VERSION ""

NS_ :

BS_:

BU_: BITSTREAM daq torque_vector InverterA OrionBMS Dashboard Main_Module bootloader InverterB Steering a_box PDU DAQ

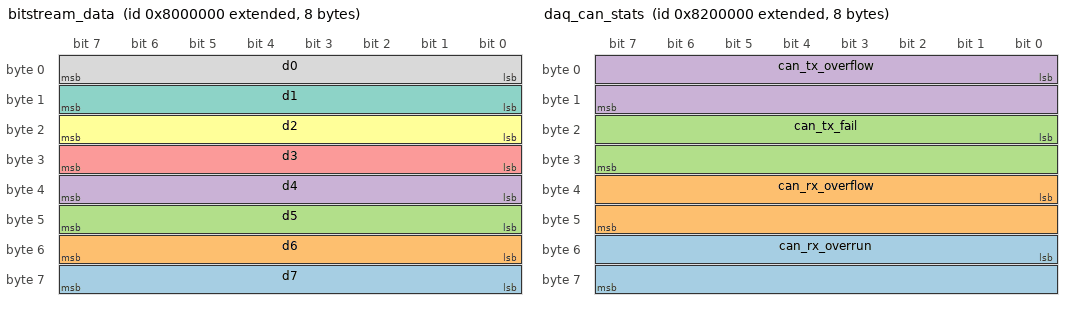
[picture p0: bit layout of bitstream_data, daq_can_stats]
BO_ 2281701376 bitstream_data: 8 BITSTREAM
 SG_ d7 : 56|8@1+ (1,0) [0|0] "" Vector__XXX
 SG_ d6 : 48|8@1+ (1,0) [0|0] "" Vector__XXX
 SG_ d5 : 40|8@1+ (1,0) [0|0] "" Vector__XXX
 SG_ d4 : 32|8@1+ (1,0) [0|0] "" Vector__XXX
 SG_ d3 : 24|8@1+ (1,0) [0|0] "" Vector__XXX
 SG_ d2 : 16|8@1+ (1,0) [0|0] "" Vector__XXX
 SG_ d1 : 8|8@1+ (1,0) [0|0] "" Vector__XXX
 SG_ d0 : 0|8@1+ (1,0) [0|0] "" Vector__XXX

BO_ 2281701888 bitstream_request: 5 BITSTREAM
 SG_ download_size : 1|32@1+ (1,0) [0|0] "" Vector__XXX
 SG_ download_request : 0|1@1+ (1,0) [0|0] "" Vector__XXX

BO_ 2281702400 main_module_bl_cmd: 5 BITSTREAM
 SG_ data : 8|32@1+ (1,0) [0|0] "" Vector__XXX
 SG_ cmd : 0|8@1+ (1,0) [0|0] "" Vector__XXX

BO_ 2281702912 dashboard_bl_cmd: 5 BITSTREAM
 SG_ data : 8|32@1+ (1,0) [0|0] "" Vector__XXX
 SG_ cmd : 0|8@1+ (1,0) [0|0] "" Vector__XXX

BO_ 2281703424 torquevector_bl_cmd: 5 BITSTREAM
 SG_ data : 8|32@1+ (1,0) [0|0] "" Vector__XXX
 SG_ cmd : 0|8@1+ (1,0) [0|0] "" Vector__XXX

BO_ 2281703936 a_box_bl_cmd: 5 BITSTREAM
 SG_ data : 8|32@1+ (1,0) [0|0] "" Vector__XXX
 SG_ cmd : 0|8@1+ (1,0) [0|0] "" Vector__XXX

BO_ 2281704448 pdu_bl_cmd: 5 BITSTREAM
 SG_ data : 8|32@1+ (1,0) [0|0] "" Vector__XXX
 SG_ cmd : 0|8@1+ (1,0) [0|0] "" Vector__XXX

BO_ 2281704960 l4_testing_bl_cmd: 5 BITSTREAM
 SG_ data : 8|32@1+ (1,0) [0|0] "" Vector__XXX
 SG_ cmd : 0|8@1+ (1,0) [0|0] "" Vector__XXX

BO_ 2281705472 f4_testing_bl_cmd: 5 BITSTREAM
 SG_ data : 8|32@1+ (1,0) [0|0] "" Vector__XXX
 SG_ cmd : 0|8@1+ (1,0) [0|0] "" Vector__XXX

BO_ 2281705984 f7_testing_bl_cmd: 5 BITSTREAM
 SG_ data : 8|32@1+ (1,0) [0|0] "" Vector__XXX
 SG_ cmd : 0|8@1+ (1,0) [0|0] "" Vector__XXX

BO_ 2281706496 daq_bl_cmd: 5 BITSTREAM
 SG_ data : 8|32@1+ (1,0) [0|0] "" Vector__XXX
 SG_ cmd : 0|8@1+ (1,0) [0|0] "" Vector__XXX

BO_ 2281707008 set_fault: 3 BITSTREAM
 SG_ value : 16|1@1+ (1,0) [0|0] "" Vector__XXX
 SG_ id : 0|16@1+ (1,0) [0|0] "" Vector__XXX

BO_ 2281707520 return_fault_control: 2 BITSTREAM
 SG_ id : 0|16@1+ (1,0) [0|0] "" Vector__XXX

BO_ 2283798528 daq_can_stats: 8 daq
 SG_ can_rx_overrun : 48|16@1+ (1,0) [0|0] "" Vector__XXX
 SG_ can_rx_overflow : 32|16@1+ (1,0) [0|0] "" Vector__XXX
 SG_ can_tx_fail : 16|16@1+ (1,0) [0|0] "" Vector__XXX
 SG_ can_tx_overflow : 0|16@1+ (1,0) [0|0] "" Vector__XXX

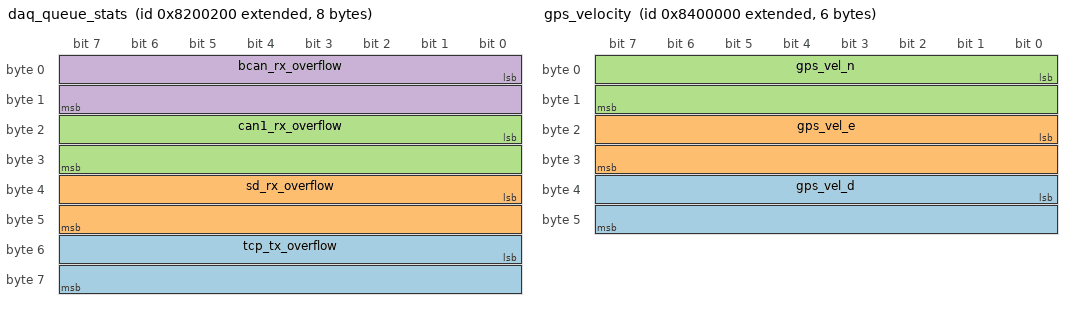
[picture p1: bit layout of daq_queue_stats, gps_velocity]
BO_ 2283799040 daq_queue_stats: 8 daq
 SG_ tcp_tx_overflow : 48|16@1+ (1,0) [0|0] "" Vector__XXX
 SG_ sd_rx_overflow : 32|16@1+ (1,0) [0|0] "" Vector__XXX
 SG_ can1_rx_overflow : 16|16@1+ (1,0) [0|0] "" Vector__XXX
 SG_ bcan_rx_overflow : 0|16@1+ (1,0) [0|0] "" Vector__XXX

BO_ 2418017280 daq_version: 8 daq
 SG_ git_hash : 0|64@1+ (1,0) [0|0] "" Vector__XXX

BO_ 2285895680 gps_velocity: 6 torque_vector
 SG_ gps_vel_d : 32|16@1- (1,0) [0|0] "m/s" Vector__XXX
 SG_ gps_vel_e : 16|16@1- (1,0) [0|0] "m/s" Vector__XXX
 SG_ gps_vel_n : 0|16@1- (1,0) [0|0] "m/s" Vector__XXX

BO_ 2285896192 gps_speed: 4 torque_vector
 SG_ gps_heading : 16|16@1- (1,0) [0|0] "none" Vector__XXX
 SG_ gps_speed : 0|16@1- (1,0) [0|0] "m/s" Vector__XXX

BO_ 2285896704 gps_position: 2 torque_vector
 SG_ height : 0|16@1- (1,0) [0|0] "m" Vector__XXX

BO_ 2285897216 gps_coordinates: 8 torque_vector
 SG_ longitude : 32|32@1- (1,0) [0|0] "deg" Vector__XXX
 SG_ latitude : 0|32@1- (1,0) [0|0] "deg" Vector__XXX

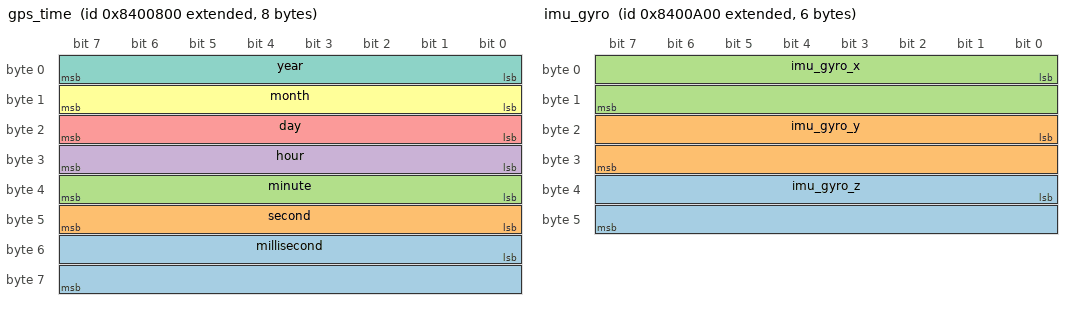
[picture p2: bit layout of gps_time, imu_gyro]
BO_ 2285897728 gps_time: 8 torque_vector
 SG_ millisecond : 48|16@1+ (1,0) [0|0] "ms" Vector__XXX
 SG_ second : 40|8@1+ (1,0) [0|0] "s" Vector__XXX
 SG_ minute : 32|8@1+ (1,0) [0|0] "m" Vector__XXX
 SG_ hour : 24|8@1+ (1,0) [0|0] "h" Vector__XXX
 SG_ day : 16|8@1+ (1,0) [0|0] "d" Vector__XXX
 SG_ month : 8|8@1+ (1,0) [0|0] "mo" Vector__XXX
 SG_ year : 0|8@1+ (1,0) [0|0] "yr" Vector__XXX

BO_ 2285898240 imu_gyro: 6 torque_vector
 SG_ imu_gyro_z : 32|16@1- (1,0) [0|0] "rad/s" Vector__XXX
 SG_ imu_gyro_y : 16|16@1- (1,0) [0|0] "rad/s" Vector__XXX
 SG_ imu_gyro_x : 0|16@1- (1,0) [0|0] "rad/s" Vector__XXX

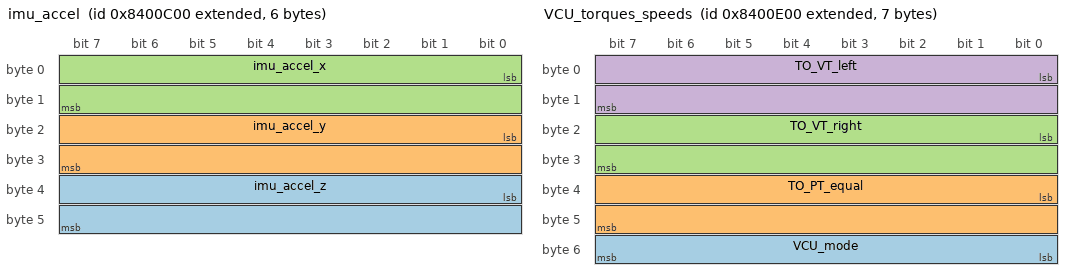
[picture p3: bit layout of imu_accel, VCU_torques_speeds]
BO_ 2285898752 imu_accel: 6 torque_vector
 SG_ imu_accel_z : 32|16@1- (1,0) [0|0] "m/s^2" Vector__XXX
 SG_ imu_accel_y : 16|16@1- (1,0) [0|0] "m/s^2" Vector__XXX
 SG_ imu_accel_x : 0|16@1- (1,0) [0|0] "m/s^2" Vector__XXX

BO_ 2285899264 VCU_torques_speeds: 7 torque_vector
 SG_ VCU_mode : 48|8@1- (1,0) [0|0] "" Vector__XXX
 SG_ TO_PT_equal : 32|16@1- (1,0) [0|0] "Nm" Vector__XXX
 SG_ TO_VT_right : 16|16@1- (1,0) [0|0] "Nm" Vector__XXX
 SG_ TO_VT_left : 0|16@1- (1,0) [0|0] "Nm" Vector__XXX

BO_ 2285899776 vcu_soc_estimate: 4 torque_vector
 SG_ Voc_estimate : 16|16@1- (1,0) [0|0] "V" Vector__XXX
 SG_ SOC_estimate : 0|16@1- (1,0) [0|0] "none" Vector__XXX

BO_ 2285900288 drive_modes: 3 torque_vector
 SG_ WS_VS_equal : 8|16@1- (1,0) [0|0] "rad/s" Vector__XXX
 SG_ VT_mode : 0|8@1- (1,0) [0|0] "" Vector__XXX

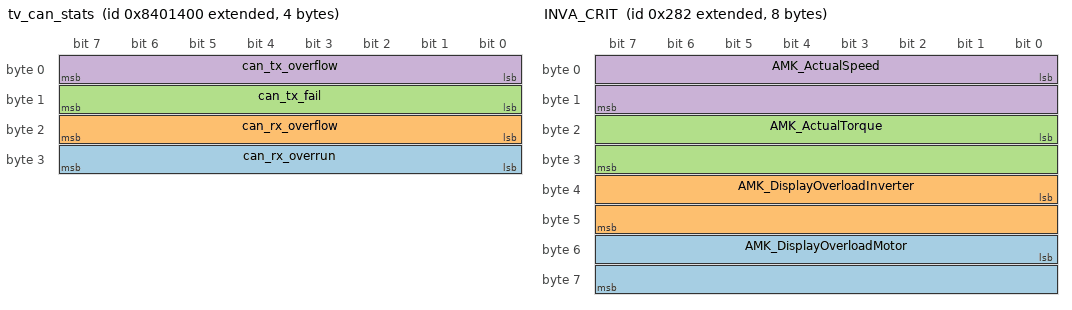
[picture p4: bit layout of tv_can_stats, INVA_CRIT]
BO_ 2285900800 tv_can_stats: 4 torque_vector
 SG_ can_rx_overrun : 24|8@1+ (1,0) [0|0] "" Vector__XXX
 SG_ can_rx_overflow : 16|8@1+ (1,0) [0|0] "" Vector__XXX
 SG_ can_tx_fail : 8|8@1+ (1,0) [0|0] "" Vector__XXX
 SG_ can_tx_overflow : 0|8@1+ (1,0) [0|0] "" Vector__XXX

BO_ 2420119040 tv_version: 8 torque_vector
 SG_ git_hash : 0|64@1+ (1,0) [0|0] "" Vector__XXX

BO_ 2151684096 fault_sync_torque_vector: 3 torque_vector
 SG_ latched : 16|1@1+ (1,0) [0|0] "" Vector__XXX
 SG_ idx : 0|16@1+ (1,0) [0|0] "" Vector__XXX

BO_ 2147484290 INVA_CRIT: 8 InverterA
 SG_ AMK_DisplayOverloadMotor : 48|16@1+ (1,0) [0|0] "" Vector__XXX
 SG_ AMK_DisplayOverloadInverter : 32|16@1+ (1,0) [0|0] "" Vector__XXX
 SG_ AMK_ActualTorque : 16|16@1- (1,0) [0|0] "%" Vector__XXX
 SG_ AMK_ActualSpeed : 0|16@1- (1,0) [0|0] "rpm" Vector__XXX

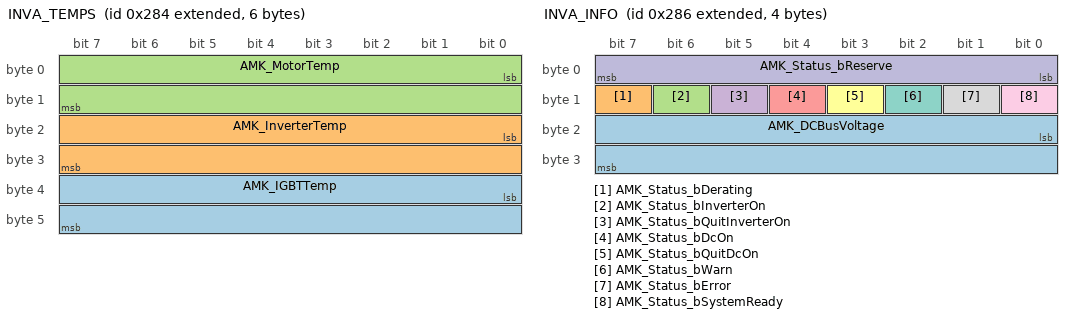
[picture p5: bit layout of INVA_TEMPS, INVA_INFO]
BO_ 2147484292 INVA_TEMPS: 6 InverterA
 SG_ AMK_IGBTTemp : 32|16@1- (1,0) [0|0] "C" Vector__XXX
 SG_ AMK_InverterTemp : 16|16@1- (1,0) [0|0] "C" Vector__XXX
 SG_ AMK_MotorTemp : 0|16@1- (1,0) [0|0] "C" Vector__XXX

BO_ 2147484294 INVA_INFO: 4 InverterA
 SG_ AMK_DCBusVoltage : 16|16@1+ (1,0) [0|0] "V" Vector__XXX
 SG_ AMK_Status_bDerating : 15|1@1+ (1,0) [0|0] "" Vector__XXX
 SG_ AMK_Status_bInverterOn : 14|1@1+ (1,0) [0|0] "" Vector__XXX
 SG_ AMK_Status_bQuitInverterOn : 13|1@1+ (1,0) [0|0] "" Vector__XXX
 SG_ AMK_Status_bDcOn : 12|1@1+ (1,0) [0|0] "" Vector__XXX
 SG_ AMK_Status_bQuitDcOn : 11|1@1+ (1,0) [0|0] "" Vector__XXX
 SG_ AMK_Status_bWarn : 10|1@1+ (1,0) [0|0] "" Vector__XXX
 SG_ AMK_Status_bError : 9|1@1+ (1,0) [0|0] "" Vector__XXX
 SG_ AMK_Status_bSystemReady : 8|1@1+ (1,0) [0|0] "" Vector__XXX
 SG_ AMK_Status_bReserve : 0|8@1+ (1,0) [0|0] "" Vector__XXX

BO_ 2147484296 INVA_ERR_1: 8 InverterA
 SG_ AMK_ErrorInfo1 : 32|32@1+ (1,0) [0|0] "" Vector__XXX
 SG_ AMK_DiagnosticNumber : 0|32@1+ (1,0) [0|0] "" Vector__XXX

BO_ 2147484304 INVA_ERR_2: 8 InverterA
 SG_ AMK_ErrorInfo3 : 32|32@1+ (1,0) [0|0] "" Vector__XXX
 SG_ AMK_ErrorInfo2 : 0|32@1+ (1,0) [0|0] "" Vector__XXX

BO_ 2147484306 INVA_PHASE_I: 4 InverterA
 SG_ AMK_PhaseUCurrent : 0|32@1- (1,0) [0|0] "" Vector__XXX

BO_ 2290089984 orion_info: 7 OrionBMS
 SG_ pack_soc : 48|8@1+ (1,0) [0|0] "%" Vector__XXX
 SG_ pack_ccl : 32|16@1+ (1,0) [0|0] "A" Vector__XXX
 SG_ pack_dcl : 16|16@1+ (1,0) [0|0] "A" Vector__XXX
 SG_ multi_output_1 : 15|1@1+ (1,0) [0|0] "" Vector__XXX
 SG_ multi_enable : 14|1@1+ (1,0) [0|0] "" Vector__XXX
 SG_ multi_output_4 : 13|1@1+ (1,0) [0|0] "" Vector__XXX
 SG_ multi_output_3 : 12|1@1+ (1,0) [0|0] "" Vector__XXX
 SG_ multi_output_2 : 11|1@1+ (1,0) [0|0] "" Vector__XXX
 SG_ reserved : 10|1@1+ (1,0) [0|0] "" Vector__XXX
 SG_ multi_input_3 : 9|1@1+ (1,0) [0|0] "" Vector__XXX
 SG_ multi_input_2 : 8|1@1+ (1,0) [0|0] "" Vector__XXX
 SG_ is_charging : 7|1@1+ (1,0) [0|0] "" Vector__XXX
 SG_ is_ready : 6|1@1+ (1,0) [0|0] "" Vector__XXX
 SG_ always_on : 5|1@1+ (1,0) [0|0] "" Vector__XXX
 SG_ multi_input : 4|1@1+ (1,0) [0|0] "" Vector__XXX
 SG_ dtc_status : 3|1@1+ (1,0) [0|0] "" Vector__XXX
 SG_ charger_safety : 2|1@1+ (1,0) [0|0] "" Vector__XXX
 SG_ charge_enable : 1|1@1+ (1,0) [0|0] "" Vector__XXX
 SG_ discharge_enable : 0|1@1+ (1,0) [0|0] "" Vector__XXX

BO_ 2290090496 orion_currents_volts: 4 OrionBMS
 SG_ pack_voltage : 16|16@1+ (1,0) [0|0] "V" Vector__XXX
 SG_ pack_current : 0|16@1- (1,0) [0|0] "A" Vector__XXX

BO_ 2290091008 orion_errors: 4 OrionBMS
 SG_ charge_limit_enforce : 31|1@1+ (1,0) [0|0] "" Vector__XXX
 SG_ input_psu : 30|1@1+ (1,0) [0|0] "" Vector__XXX
 SG_ hv_isolation : 29|1@1+ (1,0) [0|0] "" Vector__XXX
 SG_ redundant_psu : 28|1@1+ (1,0) [0|0] "" Vector__XXX
 SG_ external_comms : 27|1@1+ (1,0) [0|0] "" Vector__XXX
 SG_ thermistor : 26|1@1+ (1,0) [0|0] "" Vector__XXX
 SG_ fan_monitor : 25|1@1+ (1,0) [0|0] "" Vector__XXX
 SG_ weak_pack : 24|1@1+ (1,0) [0|0] "" Vector__XXX
 SG_ cell_asic : 23|1@1+ (1,0) [0|0] "" Vector__XXX
 SG_ max_cellv_o5v : 22|1@1+ (1,0) [0|0] "" Vector__XXX
 SG_ current_sensor : 21|1@1+ (1,0) [0|0] "" Vector__XXX
 SG_ open_wire : 20|1@1+ (1,0) [0|0] "" Vector__XXX
 SG_ low_cellv : 19|1@1+ (1,0) [0|0] "" Vector__XXX
 SG_ weak_cell : 18|1@1+ (1,0) [0|0] "" Vector__XXX
 SG_ cell_balancing_foff : 17|1@1+ (1,0) [0|0] "" Vector__XXX
 SG_ internal_comms : 16|1@1+ (1,0) [0|0] "" Vector__XXX
 SG_ reserved7 : 15|1@1+ (1,0) [0|0] "" Vector__XXX
 SG_ reserved6 : 14|1@1+ (1,0) [0|0] "" Vector__XXX
 SG_ reserved5 : 13|1@1+ (1,0) [0|0] "" Vector__XXX
 SG_ reserved4 : 12|1@1+ (1,0) [0|0] "" Vector__XXX
 SG_ reserved3 : 11|1@1+ (1,0) [0|0] "" Vector__XXX
 SG_ reserved2 : 10|1@1+ (1,0) [0|0] "" Vector__XXX
 SG_ reserved1 : 9|1@1+ (1,0) [0|0] "" Vector__XXX
 SG_ reserved0 : 8|1@1+ (1,0) [0|0] "" Vector__XXX
 SG_ pack_overheat : 7|1@1+ (1,0) [0|0] "" Vector__XXX
 SG_ min_cellv_low : 6|1@1+ (1,0) [0|0] "" Vector__XXX
 SG_ max_cellv_high : 5|1@1+ (1,0) [0|0] "" Vector__XXX
 SG_ software : 4|1@1+ (1,0) [0|0] "" Vector__XXX
 SG_ heatsink_thermistor : 3|1@1+ (1,0) [0|0] "" Vector__XXX
 SG_ internal_hardware : 2|1@1+ (1,0) [0|0] "" Vector__XXX
 SG_ charger_safety_relay : 1|1@1+ (1,0) [0|0] "" Vector__XXX
 SG_ discharge_limit_enforce : 0|1@1+ (1,0) [0|0] "" Vector__XXX

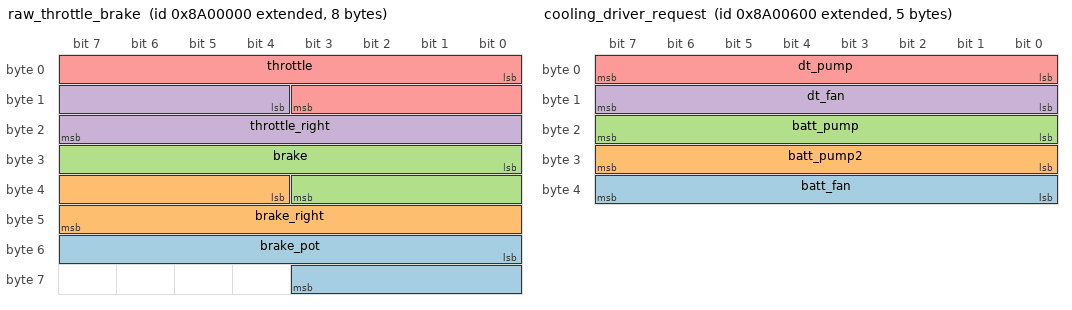
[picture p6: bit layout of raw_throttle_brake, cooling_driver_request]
BO_ 2292187136 raw_throttle_brake: 8 Dashboard
 SG_ brake_pot : 48|12@1+ (1,0) [0|0] "%" Vector__XXX
 SG_ brake_right : 36|12@1+ (1,0) [0|0] "%" Vector__XXX
 SG_ brake : 24|12@1+ (1,0) [0|0] "%" Vector__XXX
 SG_ throttle_right : 12|12@1+ (1,0) [0|0] "%" Vector__XXX
 SG_ throttle : 0|12@1+ (1,0) [0|0] "%" Vector__XXX

BO_ 2292187648 shock_front: 4 Dashboard
 SG_ right_shock : 16|16@1- (1,0) [0|0] "mm" Vector__XXX
 SG_ left_shock : 0|16@1- (1,0) [0|0] "mm" Vector__XXX

BO_ 2292188160 load_sensor_readings_dash: 8 Dashboard
 SG_ right_load_sensor : 32|32@1- (1,0) [0|0] "N" Vector__XXX
 SG_ left_load_sensor : 0|32@1- (1,0) [0|0] "N" Vector__XXX

BO_ 2292188672 cooling_driver_request: 5 Dashboard
 SG_ batt_fan : 32|8@1+ (1,0) [0|100] "%" Vector__XXX
 SG_ batt_pump2 : 24|8@1+ (1,0) [0|0] "" Vector__XXX
 SG_ batt_pump : 16|8@1+ (1,0) [0|0] "" Vector__XXX
 SG_ dt_fan : 8|8@1+ (1,0) [0|100] "%" Vector__XXX
 SG_ dt_pump : 0|8@1+ (1,0) [0|0] "" Vector__XXX

BO_ 2292189184 filt_throttle_brake: 3 Dashboard
 SG_ brake : 12|12@1+ (1,0) [0|0] "%" Vector__XXX
 SG_ throttle : 0|12@1+ (1,0) [0|0] "%" Vector__XXX

BO_ 2292189696 start_button: 1 Dashboard
 SG_ start : 0|1@1+ (1,0) [0|0] "" Vector__XXX

BO_ 2292190208 dashboard_mcu_temp: 2 Dashboard
 SG_ mcu_temp : 0|16@1- (1,0) [0|0] "" Vector__XXX

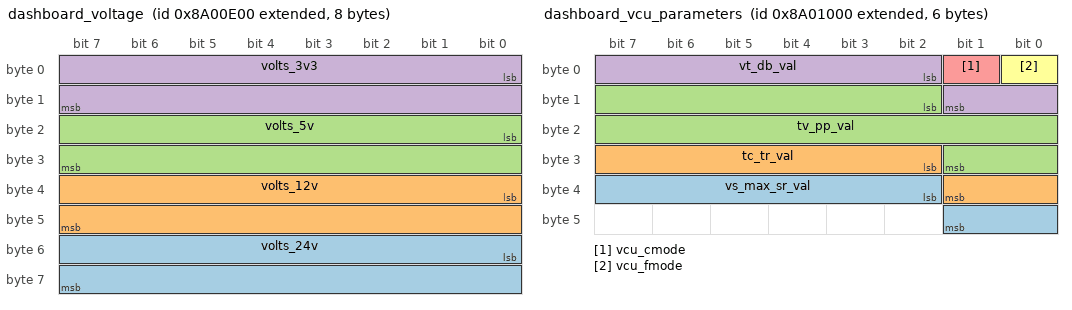
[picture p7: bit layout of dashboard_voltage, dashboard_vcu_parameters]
BO_ 2292190720 dashboard_voltage: 8 Dashboard
 SG_ volts_24v : 48|16@1+ (1,0) [0|0] "V" Vector__XXX
 SG_ volts_12v : 32|16@1+ (1,0) [0|0] "V" Vector__XXX
 SG_ volts_5v : 16|16@1+ (1,0) [0|0] "V" Vector__XXX
 SG_ volts_3v3 : 0|16@1+ (1,0) [0|0] "V" Vector__XXX

BO_ 2292191232 dashboard_vcu_parameters: 6 Dashboard
 SG_ vs_max_sr_val : 34|8@1+ (1,0) [0|0] "" Vector__XXX
 SG_ tc_tr_val : 26|8@1+ (1,0) [0|0] "" Vector__XXX
 SG_ tv_pp_val : 10|16@1+ (1,0) [0|0] "" Vector__XXX
 SG_ vt_db_val : 2|8@1+ (1,0) [0|0] "" Vector__XXX
 SG_ vcu_cmode : 1|1@1+ (1,0) [0|0] "" Vector__XXX
 SG_ vcu_fmode : 0|1@1+ (1,0) [0|0] "" Vector__XXX

BO_ 2292191744 dashboard_start_logging: 1 Dashboard
 SG_ logging_enabled : 0|1@1+ (1,0) [0|0] "" Vector__XXX

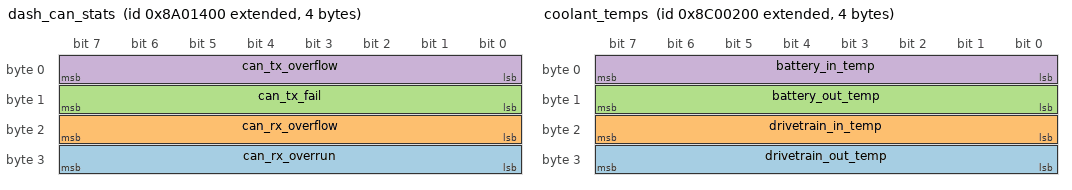
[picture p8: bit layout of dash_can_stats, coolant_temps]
BO_ 2292192256 dash_can_stats: 4 Dashboard
 SG_ can_rx_overrun : 24|8@1+ (1,0) [0|0] "" Vector__XXX
 SG_ can_rx_overflow : 16|8@1+ (1,0) [0|0] "" Vector__XXX
 SG_ can_tx_fail : 8|8@1+ (1,0) [0|0] "" Vector__XXX
 SG_ can_tx_overflow : 0|8@1+ (1,0) [0|0] "" Vector__XXX

BO_ 2426410496 dash_version: 8 Dashboard
 SG_ git_hash : 0|64@1+ (1,0) [0|0] "" Vector__XXX

BO_ 2157975552 fault_sync_dashboard: 3 Dashboard
 SG_ latched : 16|1@1+ (1,0) [0|0] "" Vector__XXX
 SG_ idx : 0|16@1+ (1,0) [0|0] "" Vector__XXX

BO_ 2292193792 daq_response_DASHBOARD_VCAN: 8 Dashboard
 SG_ daq_response : 0|64@1+ (1,0) [0|0] "" Vector__XXX

BO_ 2294284288 main_hb: 2 Main_Module
 SG_ precharge_state : 8|1@1+ (1,0) [0|0] "" Vector__XXX
 SG_ car_state : 0|8@1+ (1,0) [0|0] "" Vector__XXX

BO_ 2294284800 coolant_temps: 4 Main_Module
 SG_ drivetrain_out_temp : 24|8@1- (1,0) [0|0] "C" Vector__XXX
 SG_ drivetrain_in_temp : 16|8@1- (1,0) [0|0] "C" Vector__XXX
 SG_ battery_out_temp : 8|8@1- (1,0) [0|0] "C" Vector__XXX
 SG_ battery_in_temp : 0|8@1- (1,0) [0|0] "C" Vector__XXX

BO_ 2294285312 gearbox: 2 Main_Module
 SG_ r_temp : 8|8@1- (1,0) [0|0] "C" Vector__XXX
 SG_ l_temp : 0|8@1- (1,0) [0|0] "C" Vector__XXX

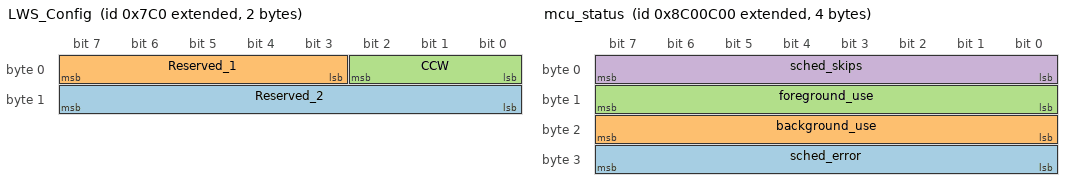
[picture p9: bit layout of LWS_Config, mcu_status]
BO_ 2147485632 LWS_Config: 2 Main_Module
 SG_ Reserved_2 : 8|8@1+ (1,0) [0|0] "" Vector__XXX
 SG_ Reserved_1 : 3|5@1+ (1,0) [0|0] "" Vector__XXX
 SG_ CCW : 0|3@1+ (1,0) [0|0] "" Vector__XXX

BO_ 2294286336 load_sensor_readings: 8 Main_Module
 SG_ right_load_sensor : 32|32@1- (1,0) [0|0] "N" Vector__XXX
 SG_ left_load_sensor : 0|32@1- (1,0) [0|0] "N" Vector__XXX

BO_ 2294286848 shock_rear: 4 Main_Module
 SG_ right_shock : 16|16@1- (1,0) [0|0] "mm" Vector__XXX
 SG_ left_shock : 0|16@1- (1,0) [0|0] "mm" Vector__XXX

BO_ 2294287360 mcu_status: 4 Main_Module
 SG_ sched_error : 24|8@1+ (1,0) [0|0] "" Vector__XXX
 SG_ background_use : 16|8@1+ (1,0) [0|0] "" Vector__XXX
 SG_ foreground_use : 8|8@1+ (1,0) [0|0] "" Vector__XXX
 SG_ sched_skips : 0|8@1+ (1,0) [0|0] "" Vector__XXX

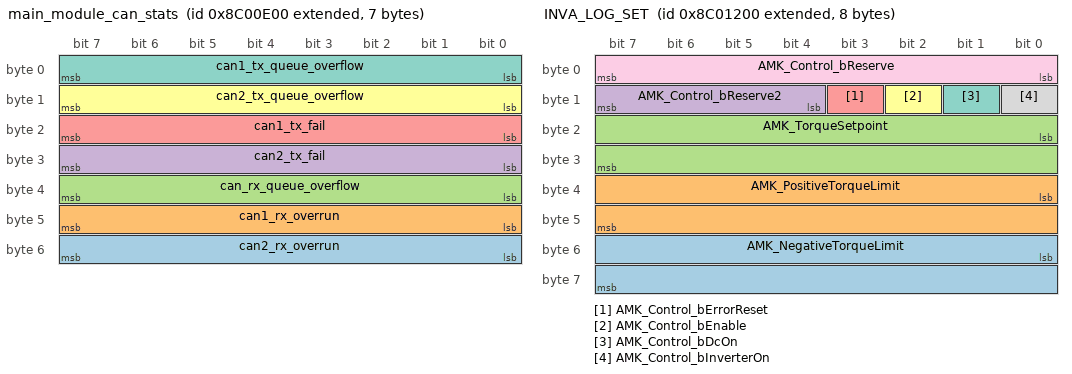
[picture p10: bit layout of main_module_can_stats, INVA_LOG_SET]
BO_ 2294287872 main_module_can_stats: 7 Main_Module
 SG_ can2_rx_overrun : 48|8@1+ (1,0) [0|0] "" Vector__XXX
 SG_ can1_rx_overrun : 40|8@1+ (1,0) [0|0] "" Vector__XXX
 SG_ can_rx_queue_overflow : 32|8@1+ (1,0) [0|0] "" Vector__XXX
 SG_ can2_tx_fail : 24|8@1+ (1,0) [0|0] "" Vector__XXX
 SG_ can1_tx_fail : 16|8@1+ (1,0) [0|0] "" Vector__XXX
 SG_ can2_tx_queue_overflow : 8|8@1+ (1,0) [0|0] "" Vector__XXX
 SG_ can1_tx_queue_overflow : 0|8@1+ (1,0) [0|0] "" Vector__XXX

BO_ 2294288384 num_mc_skips: 4 Main_Module
 SG_ noise_l : 16|16@1+ (1,0) [0|0] "" Vector__XXX
 SG_ noise_r : 0|16@1+ (1,0) [0|0] "" Vector__XXX

BO_ 2294288896 INVA_LOG_SET: 8 Main_Module
 SG_ AMK_NegativeTorqueLimit : 48|16@1- (1,0) [0|0] "Nm" Vector__XXX
 SG_ AMK_PositiveTorqueLimit : 32|16@1- (1,0) [0|0] "Nm" Vector__XXX
 SG_ AMK_TorqueSetpoint : 16|16@1- (1,0) [0|0] "Nm" Vector__XXX
 SG_ AMK_Control_bReserve2 : 12|4@1+ (1,0) [0|0] "" Vector__XXX
 SG_ AMK_Control_bErrorReset : 11|1@1+ (1,0) [0|0] "" Vector__XXX
 SG_ AMK_Control_bEnable : 10|1@1+ (1,0) [0|0] "" Vector__XXX
 SG_ AMK_Control_bDcOn : 9|1@1+ (1,0) [0|0] "" Vector__XXX
 SG_ AMK_Control_bInverterOn : 8|1@1+ (1,0) [0|0] "" Vector__XXX
 SG_ AMK_Control_bReserve : 0|8@1+ (1,0) [0|0] "" Vector__XXX

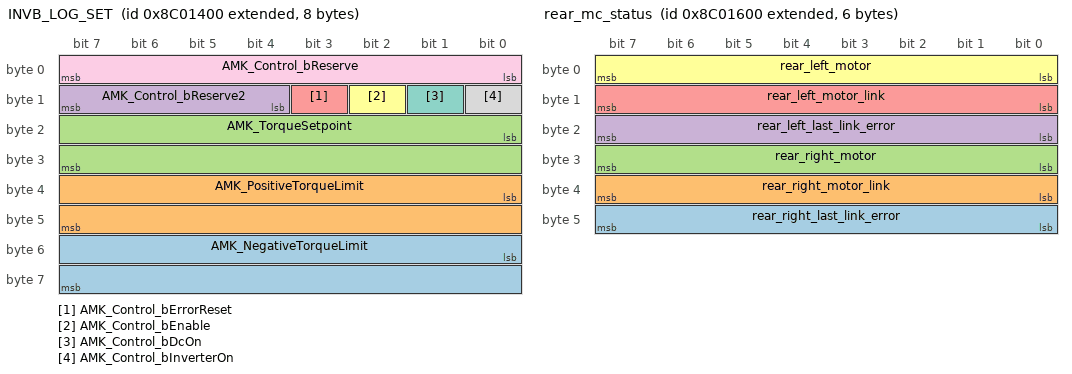
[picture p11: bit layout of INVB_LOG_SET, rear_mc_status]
BO_ 2294289408 INVB_LOG_SET: 8 Main_Module
 SG_ AMK_NegativeTorqueLimit : 48|16@1- (1,0) [0|0] "Nm" Vector__XXX
 SG_ AMK_PositiveTorqueLimit : 32|16@1- (1,0) [0|0] "Nm" Vector__XXX
 SG_ AMK_TorqueSetpoint : 16|16@1- (1,0) [0|0] "Nm" Vector__XXX
 SG_ AMK_Control_bReserve2 : 12|4@1+ (1,0) [0|0] "" Vector__XXX
 SG_ AMK_Control_bErrorReset : 11|1@1+ (1,0) [0|0] "" Vector__XXX
 SG_ AMK_Control_bEnable : 10|1@1+ (1,0) [0|0] "" Vector__XXX
 SG_ AMK_Control_bDcOn : 9|1@1+ (1,0) [0|0] "" Vector__XXX
 SG_ AMK_Control_bInverterOn : 8|1@1+ (1,0) [0|0] "" Vector__XXX
 SG_ AMK_Control_bReserve : 0|8@1+ (1,0) [0|0] "" Vector__XXX

BO_ 2294289920 rear_mc_status: 6 Main_Module
 SG_ rear_right_last_link_error : 40|8@1+ (1,0) [0|0] "" Vector__XXX
 SG_ rear_right_motor_link : 32|8@1+ (1,0) [0|0] "" Vector__XXX
 SG_ rear_right_motor : 24|8@1+ (1,0) [0|0] "" Vector__XXX
 SG_ rear_left_last_link_error : 16|8@1+ (1,0) [0|0] "" Vector__XXX
 SG_ rear_left_motor_link : 8|8@1+ (1,0) [0|0] "" Vector__XXX
 SG_ rear_left_motor : 0|8@1+ (1,0) [0|0] "" Vector__XXX

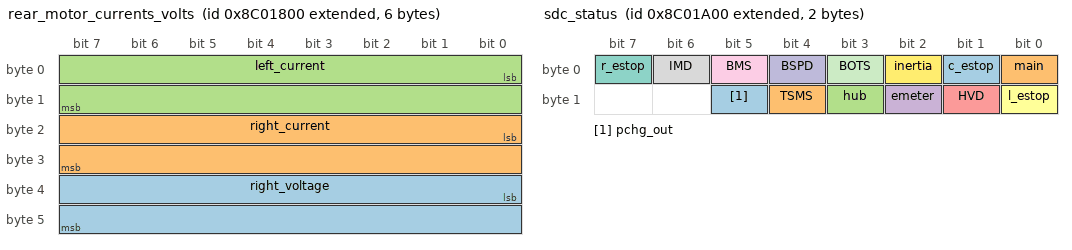
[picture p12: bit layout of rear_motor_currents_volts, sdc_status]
BO_ 2294290432 rear_motor_currents_volts: 6 Main_Module
 SG_ right_voltage : 32|16@1+ (1,0) [0|0] "Voltx10" Vector__XXX
 SG_ right_current : 16|16@1+ (1,0) [0|0] "Amp" Vector__XXX
 SG_ left_current : 0|16@1+ (1,0) [0|0] "Amp" Vector__XXX

BO_ 2294290944 sdc_status: 2 Main_Module
 SG_ pchg_out : 13|1@1+ (1,0) [0|0] "" Vector__XXX
 SG_ TSMS : 12|1@1+ (1,0) [0|0] "" Vector__XXX
 SG_ hub : 11|1@1+ (1,0) [0|0] "" Vector__XXX
 SG_ emeter : 10|1@1+ (1,0) [0|0] "" Vector__XXX
 SG_ HVD : 9|1@1+ (1,0) [0|0] "" Vector__XXX
 SG_ l_estop : 8|1@1+ (1,0) [0|0] "" Vector__XXX
 SG_ r_estop : 7|1@1+ (1,0) [0|0] "" Vector__XXX
 SG_ IMD : 6|1@1+ (1,0) [0|0] "" Vector__XXX
 SG_ BMS : 5|1@1+ (1,0) [0|0] "" Vector__XXX
 SG_ BSPD : 4|1@1+ (1,0) [0|0] "" Vector__XXX
 SG_ BOTS : 3|1@1+ (1,0) [0|0] "" Vector__XXX
 SG_ inertia : 2|1@1+ (1,0) [0|0] "" Vector__XXX
 SG_ c_estop : 1|1@1+ (1,0) [0|0] "" Vector__XXX
 SG_ main : 0|1@1+ (1,0) [0|0] "" Vector__XXX

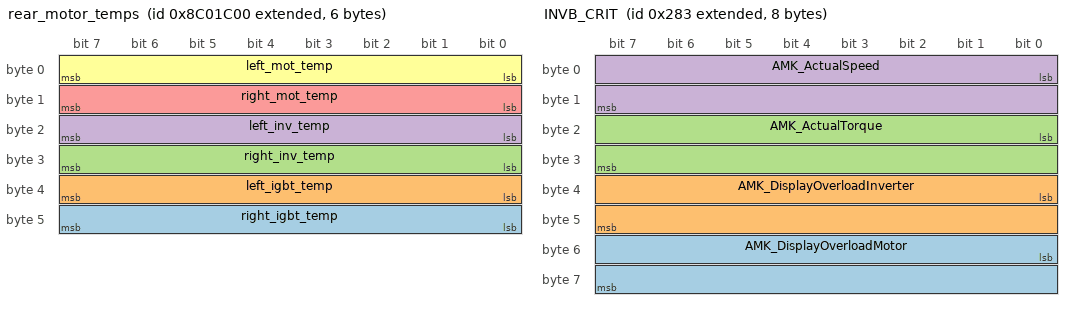
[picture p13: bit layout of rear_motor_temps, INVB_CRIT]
BO_ 2294291456 rear_motor_temps: 6 Main_Module
 SG_ right_igbt_temp : 40|8@1+ (1,0) [0|0] "C" Vector__XXX
 SG_ left_igbt_temp : 32|8@1+ (1,0) [0|0] "C" Vector__XXX
 SG_ right_inv_temp : 24|8@1+ (1,0) [0|0] "C" Vector__XXX
 SG_ left_inv_temp : 16|8@1+ (1,0) [0|0] "C" Vector__XXX
 SG_ right_mot_temp : 8|8@1+ (1,0) [0|0] "C" Vector__XXX
 SG_ left_mot_temp : 0|8@1+ (1,0) [0|0] "C" Vector__XXX

BO_ 2294291968 rear_wheel_speeds: 4 Main_Module
 SG_ right_speed_sensor : 16|16@1+ (1,0) [0|0] "rad/s" Vector__XXX
 SG_ left_speed_sensor : 0|16@1+ (1,0) [0|0] "rad/s" Vector__XXX

BO_ 2294292480 simulated_tv: 4 Main_Module
 SG_ right_tv : 16|16@1+ (1,0) [0|0] "rad/s" Vector__XXX
 SG_ left_tv : 0|16@1+ (1,0) [0|0] "rad/s" Vector__XXX

BO_ 2428510720 main_version: 8 Main_Module
 SG_ git_hash : 0|64@1+ (1,0) [0|0] "" Vector__XXX

BO_ 2160075776 fault_sync_main_module: 3 Main_Module
 SG_ latched : 16|1@1+ (1,0) [0|0] "" Vector__XXX
 SG_ idx : 0|16@1+ (1,0) [0|0] "" Vector__XXX

BO_ 2294294016 daq_response_MAIN_MODULE_VCAN: 8 Main_Module
 SG_ daq_response : 0|64@1+ (1,0) [0|0] "" Vector__XXX

BO_ 2296381440 main_module_bl_resp: 5 bootloader
 SG_ data : 8|32@1+ (1,0) [0|0] "" Vector__XXX
 SG_ cmd : 0|8@1+ (1,0) [0|0] "" Vector__XXX

BO_ 2296381952 dashboard_bl_resp: 5 bootloader
 SG_ data : 8|32@1+ (1,0) [0|0] "" Vector__XXX
 SG_ cmd : 0|8@1+ (1,0) [0|0] "" Vector__XXX

BO_ 2296382464 torquevector_bl_resp: 5 bootloader
 SG_ data : 8|32@1+ (1,0) [0|0] "" Vector__XXX
 SG_ cmd : 0|8@1+ (1,0) [0|0] "" Vector__XXX

BO_ 2296382976 a_box_bl_resp: 5 bootloader
 SG_ data : 8|32@1+ (1,0) [0|0] "" Vector__XXX
 SG_ cmd : 0|8@1+ (1,0) [0|0] "" Vector__XXX

BO_ 2296383488 pdu_bl_resp: 5 bootloader
 SG_ data : 8|32@1+ (1,0) [0|0] "" Vector__XXX
 SG_ cmd : 0|8@1+ (1,0) [0|0] "" Vector__XXX

BO_ 2296384000 l4_testing_bl_resp: 5 bootloader
 SG_ data : 8|32@1+ (1,0) [0|0] "" Vector__XXX
 SG_ cmd : 0|8@1+ (1,0) [0|0] "" Vector__XXX

BO_ 2296384512 f4_testing_bl_resp: 5 bootloader
 SG_ data : 8|32@1+ (1,0) [0|0] "" Vector__XXX
 SG_ cmd : 0|8@1+ (1,0) [0|0] "" Vector__XXX

BO_ 2296385024 f7_testing_bl_resp: 5 bootloader
 SG_ data : 8|32@1+ (1,0) [0|0] "" Vector__XXX
 SG_ cmd : 0|8@1+ (1,0) [0|0] "" Vector__XXX

BO_ 2296385536 daq_bl_resp: 5 bootloader
 SG_ data : 8|32@1+ (1,0) [0|0] "" Vector__XXX
 SG_ cmd : 0|8@1+ (1,0) [0|0] "" Vector__XXX

BO_ 2147484291 INVB_CRIT: 8 InverterB
 SG_ AMK_DisplayOverloadMotor : 48|16@1+ (1,0) [0|0] "" Vector__XXX
 SG_ AMK_DisplayOverloadInverter : 32|16@1+ (1,0) [0|0] "" Vector__XXX
 SG_ AMK_ActualTorque : 16|16@1- (1,0) [0|0] "%" Vector__XXX
 SG_ AMK_ActualSpeed : 0|16@1- (1,0) [0|0] "rpm" Vector__XXX

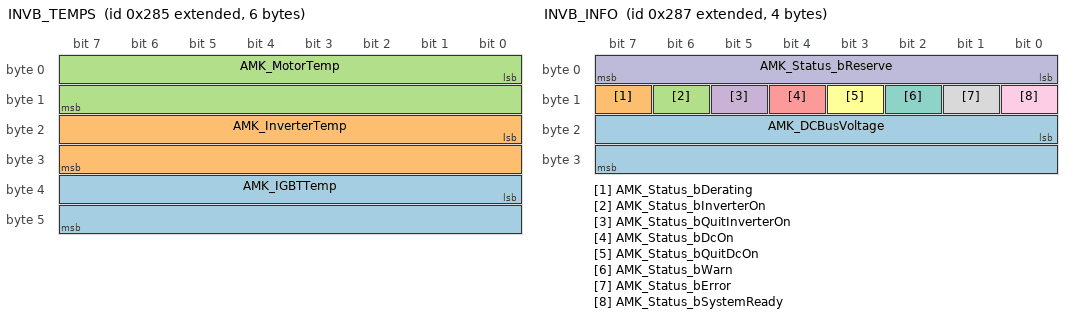
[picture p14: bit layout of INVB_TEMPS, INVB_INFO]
BO_ 2147484293 INVB_TEMPS: 6 InverterB
 SG_ AMK_IGBTTemp : 32|16@1- (1,0) [0|0] "C" Vector__XXX
 SG_ AMK_InverterTemp : 16|16@1- (1,0) [0|0] "C" Vector__XXX
 SG_ AMK_MotorTemp : 0|16@1- (1,0) [0|0] "C" Vector__XXX

BO_ 2147484295 INVB_INFO: 4 InverterB
 SG_ AMK_DCBusVoltage : 16|16@1+ (1,0) [0|0] "V" Vector__XXX
 SG_ AMK_Status_bDerating : 15|1@1+ (1,0) [0|0] "" Vector__XXX
 SG_ AMK_Status_bInverterOn : 14|1@1+ (1,0) [0|0] "" Vector__XXX
 SG_ AMK_Status_bQuitInverterOn : 13|1@1+ (1,0) [0|0] "" Vector__XXX
 SG_ AMK_Status_bDcOn : 12|1@1+ (1,0) [0|0] "" Vector__XXX
 SG_ AMK_Status_bQuitDcOn : 11|1@1+ (1,0) [0|0] "" Vector__XXX
 SG_ AMK_Status_bWarn : 10|1@1+ (1,0) [0|0] "" Vector__XXX
 SG_ AMK_Status_bError : 9|1@1+ (1,0) [0|0] "" Vector__XXX
 SG_ AMK_Status_bSystemReady : 8|1@1+ (1,0) [0|0] "" Vector__XXX
 SG_ AMK_Status_bReserve : 0|8@1+ (1,0) [0|0] "" Vector__XXX

BO_ 2147484297 INVB_ERR_1: 8 InverterB
 SG_ AMK_ErrorInfo1 : 32|32@1+ (1,0) [0|0] "" Vector__XXX
 SG_ AMK_DiagnosticNumber : 0|32@1+ (1,0) [0|0] "" Vector__XXX

BO_ 2147484305 INVB_ERR_2: 8 InverterB
 SG_ AMK_ErrorInfo3 : 32|32@1+ (1,0) [0|0] "" Vector__XXX
 SG_ AMK_ErrorInfo2 : 0|32@1+ (1,0) [0|0] "" Vector__XXX

BO_ 2147484307 INVB_PHASE_I: 4 InverterB
 SG_ AMK_PhaseUCurrent : 0|32@1- (1,0) [0|0] "" Vector__XXX

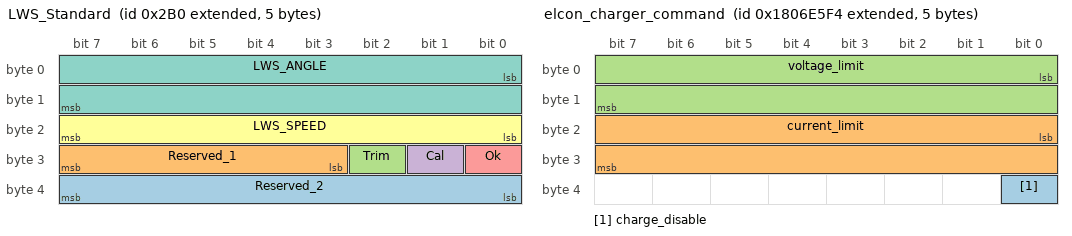
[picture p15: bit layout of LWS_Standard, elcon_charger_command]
BO_ 2147484336 LWS_Standard: 5 Steering
 SG_ Reserved_2 : 32|8@1+ (1,0) [0|0] "" Vector__XXX
 SG_ Reserved_1 : 27|5@1+ (1,0) [0|0] "" Vector__XXX
 SG_ Trim : 26|1@1+ (1,0) [0|0] "" Vector__XXX
 SG_ Cal : 25|1@1+ (1,0) [0|0] "" Vector__XXX
 SG_ Ok : 24|1@1+ (1,0) [0|0] "" Vector__XXX
 SG_ LWS_SPEED : 16|8@1+ (1,0) [0|0] "deg/s" Vector__XXX
 SG_ LWS_ANGLE : 0|16@1- (1,0) [0|0] "deg" Vector__XXX

BO_ 2302672896 precharge_hb: 2 a_box
 SG_ BMS : 8|8@1+ (1,0) [0|0] "" Vector__XXX
 SG_ IMD : 0|8@1+ (1,0) [0|0] "" Vector__XXX

BO_ 2550588916 elcon_charger_command: 5 a_box
 SG_ charge_disable : 32|1@1+ (1,0) [0|0] "" Vector__XXX
 SG_ current_limit : 16|16@1+ (1,0) [0|0] "A" Vector__XXX
 SG_ voltage_limit : 0|16@1+ (1,0) [0|0] "V" Vector__XXX

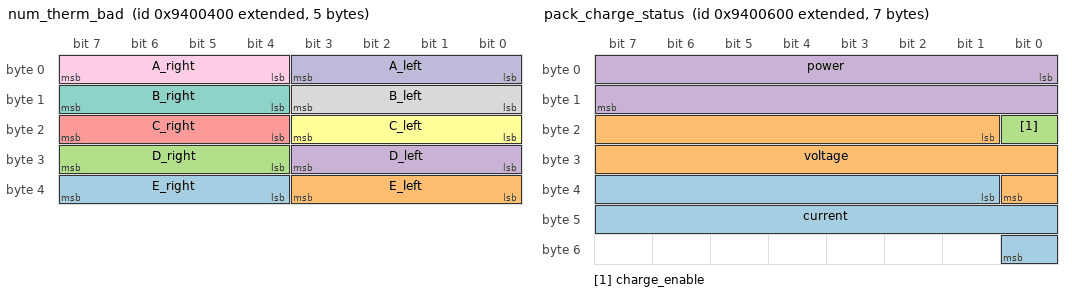
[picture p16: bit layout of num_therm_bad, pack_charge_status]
BO_ 2302673920 num_therm_bad: 5 a_box
 SG_ E_right : 36|4@1+ (1,0) [0|0] "" Vector__XXX
 SG_ E_left : 32|4@1+ (1,0) [0|0] "" Vector__XXX
 SG_ D_right : 28|4@1+ (1,0) [0|0] "" Vector__XXX
 SG_ D_left : 24|4@1+ (1,0) [0|0] "" Vector__XXX
 SG_ C_right : 20|4@1+ (1,0) [0|0] "" Vector__XXX
 SG_ C_left : 16|4@1+ (1,0) [0|0] "" Vector__XXX
 SG_ B_right : 12|4@1+ (1,0) [0|0] "" Vector__XXX
 SG_ B_left : 8|4@1+ (1,0) [0|0] "" Vector__XXX
 SG_ A_right : 4|4@1+ (1,0) [0|0] "" Vector__XXX
 SG_ A_left : 0|4@1+ (1,0) [0|0] "" Vector__XXX

BO_ 2302674432 pack_charge_status: 7 a_box
 SG_ current : 33|16@1+ (1,0) [0|0] "A" Vector__XXX
 SG_ voltage : 17|16@1+ (1,0) [0|0] "V" Vector__XXX
 SG_ charge_enable : 16|1@1+ (1,0) [0|0] "" Vector__XXX
 SG_ power : 0|16@1+ (1,0) [0|0] "W" Vector__XXX

BO_ 2302674944 max_cell_temp: 2 a_box
 SG_ max_temp : 0|16@1- (1,0) [0|0] "" Vector__XXX

BO_ 2302675456 mod_cell_temp_avg_a_b_c: 6 a_box
 SG_ temp_C : 32|16@1- (1,0) [0|0] "" Vector__XXX
 SG_ temp_B : 16|16@1- (1,0) [0|0] "" Vector__XXX
 SG_ temp_A : 0|16@1- (1,0) [0|0] "" Vector__XXX

BO_ 2302675968 mod_cell_temp_avg_d_e: 4 a_box
 SG_ temp_E : 16|16@1- (1,0) [0|0] "" Vector__XXX
 SG_ temp_D : 0|16@1- (1,0) [0|0] "" Vector__XXX

BO_ 2302676480 mod_cell_temp_max_a_b_c: 6 a_box
 SG_ temp_C : 32|16@1- (1,0) [0|0] "" Vector__XXX
 SG_ temp_B : 16|16@1- (1,0) [0|0] "" Vector__XXX
 SG_ temp_A : 0|16@1- (1,0) [0|0] "" Vector__XXX

BO_ 2302676992 mod_cell_temp_max_d_e: 4 a_box
 SG_ temp_E : 16|16@1- (1,0) [0|0] "" Vector__XXX
 SG_ temp_D : 0|16@1- (1,0) [0|0] "" Vector__XXX

BO_ 2302677504 mod_cell_temp_min_a_b_c: 6 a_box
 SG_ temp_C : 32|16@1- (1,0) [0|0] "" Vector__XXX
 SG_ temp_B : 16|16@1- (1,0) [0|0] "" Vector__XXX
 SG_ temp_A : 0|16@1- (1,0) [0|0] "" Vector__XXX

BO_ 2302678016 mod_cell_temp_min_d_e: 4 a_box
 SG_ temp_E : 16|16@1- (1,0) [0|0] "" Vector__XXX
 SG_ temp_D : 0|16@1- (1,0) [0|0] "" Vector__XXX

BO_ 2302678528 raw_cell_temp_module1: 5 a_box
 SG_ temp_right : 24|16@1- (1,0) [0|0] "C" Vector__XXX
 SG_ temp_left : 8|16@1- (1,0) [0|0] "C" Vector__XXX
 SG_ index : 0|8@1+ (1,0) [0|0] "" Vector__XXX

BO_ 2302679040 raw_cell_temp_module2: 5 a_box
 SG_ temp_right : 24|16@1- (1,0) [0|0] "C" Vector__XXX
 SG_ temp_left : 8|16@1- (1,0) [0|0] "C" Vector__XXX
 SG_ index : 0|8@1+ (1,0) [0|0] "" Vector__XXX

BO_ 2302679552 raw_cell_temp_module3: 5 a_box
 SG_ temp_right : 24|16@1- (1,0) [0|0] "C" Vector__XXX
 SG_ temp_left : 8|16@1- (1,0) [0|0] "C" Vector__XXX
 SG_ index : 0|8@1+ (1,0) [0|0] "" Vector__XXX

BO_ 2302680064 raw_cell_temp_module4: 5 a_box
 SG_ temp_right : 24|16@1- (1,0) [0|0] "C" Vector__XXX
 SG_ temp_left : 8|16@1- (1,0) [0|0] "C" Vector__XXX
 SG_ index : 0|8@1+ (1,0) [0|0] "" Vector__XXX

BO_ 2302680576 raw_cell_temp_module5: 5 a_box
 SG_ temp_right : 24|16@1- (1,0) [0|0] "C" Vector__XXX
 SG_ temp_left : 8|16@1- (1,0) [0|0] "C" Vector__XXX
 SG_ index : 0|8@1+ (1,0) [0|0] "" Vector__XXX

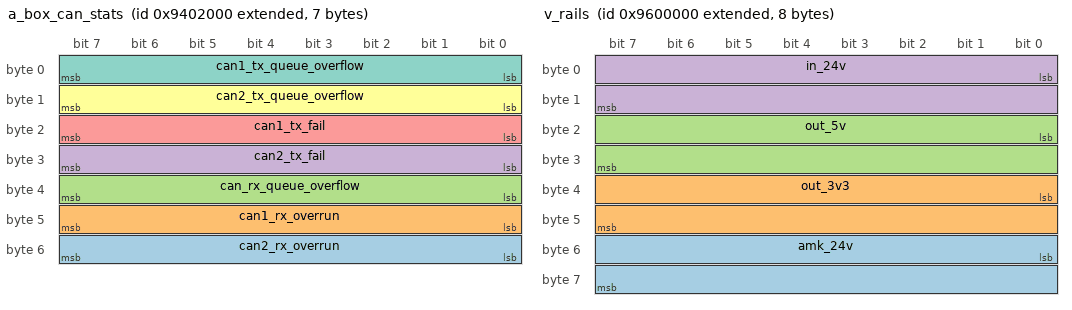
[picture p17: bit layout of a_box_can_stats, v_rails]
BO_ 2302681088 a_box_can_stats: 7 a_box
 SG_ can2_rx_overrun : 48|8@1+ (1,0) [0|0] "" Vector__XXX
 SG_ can1_rx_overrun : 40|8@1+ (1,0) [0|0] "" Vector__XXX
 SG_ can_rx_queue_overflow : 32|8@1+ (1,0) [0|0] "" Vector__XXX
 SG_ can2_tx_fail : 24|8@1+ (1,0) [0|0] "" Vector__XXX
 SG_ can1_tx_fail : 16|8@1+ (1,0) [0|0] "" Vector__XXX
 SG_ can2_tx_queue_overflow : 8|8@1+ (1,0) [0|0] "" Vector__XXX
 SG_ can1_tx_queue_overflow : 0|8@1+ (1,0) [0|0] "" Vector__XXX

BO_ 2302681600 i_sense: 4 a_box
 SG_ current_channel_2 : 16|16@1- (1,0) [0|0] "A" Vector__XXX
 SG_ current_channel_1 : 0|16@1- (1,0) [0|0] "A" Vector__XXX

BO_ 2436899840 abox_version: 8 a_box
 SG_ git_hash : 0|64@1+ (1,0) [0|0] "" Vector__XXX

BO_ 2168464896 fault_sync_a_box: 3 a_box
 SG_ latched : 16|1@1+ (1,0) [0|0] "" Vector__XXX
 SG_ idx : 0|16@1+ (1,0) [0|0] "" Vector__XXX

BO_ 2302683136 daq_response_A_BOX_VCAN: 8 a_box
 SG_ daq_response : 0|64@1+ (1,0) [0|0] "" Vector__XXX

BO_ 2304770048 v_rails: 8 PDU
 SG_ amk_24v : 48|16@1+ (1,0) [0|0] "mV" Vector__XXX
 SG_ out_3v3 : 32|16@1+ (1,0) [0|0] "mV" Vector__XXX
 SG_ out_5v : 16|16@1+ (1,0) [0|0] "mV" Vector__XXX
 SG_ in_24v : 0|16@1+ (1,0) [0|0] "mV" Vector__XXX

BO_ 2304770560 rail_currents: 4 PDU
 SG_ i_5v : 16|16@1+ (1,0) [0|0] "mA" Vector__XXX
 SG_ i_24v : 0|16@1+ (1,0) [0|0] "mA" Vector__XXX

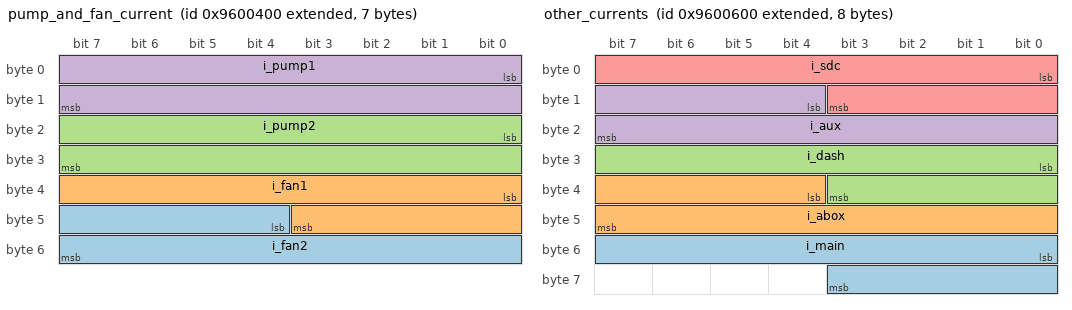
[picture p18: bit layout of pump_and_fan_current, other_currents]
BO_ 2304771072 pump_and_fan_current: 7 PDU
 SG_ i_fan2 : 44|12@1+ (1,0) [0|0] "mA" Vector__XXX
 SG_ i_fan1 : 32|12@1+ (1,0) [0|0] "mA" Vector__XXX
 SG_ i_pump2 : 16|16@1+ (1,0) [0|0] "mA" Vector__XXX
 SG_ i_pump1 : 0|16@1+ (1,0) [0|0] "mA" Vector__XXX

BO_ 2304771584 other_currents: 8 PDU
 SG_ i_main : 48|12@1+ (1,0) [0|0] "mA" Vector__XXX
 SG_ i_abox : 36|12@1+ (1,0) [0|0] "mA" Vector__XXX
 SG_ i_dash : 24|12@1+ (1,0) [0|0] "mA" Vector__XXX
 SG_ i_aux : 12|12@1+ (1,0) [0|0] "mA" Vector__XXX
 SG_ i_sdc : 0|12@1+ (1,0) [0|0] "mA" Vector__XXX

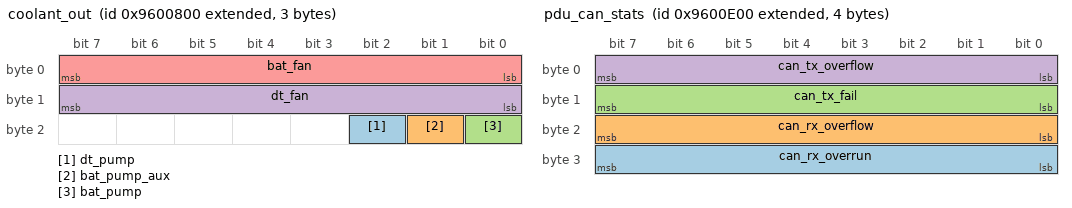
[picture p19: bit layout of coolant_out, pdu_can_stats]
BO_ 2304772096 coolant_out: 3 PDU
 SG_ dt_pump : 18|1@1+ (1,0) [0|0] "" Vector__XXX
 SG_ bat_pump_aux : 17|1@1+ (1,0) [0|0] "" Vector__XXX
 SG_ bat_pump : 16|1@1+ (1,0) [0|0] "" Vector__XXX
 SG_ dt_fan : 8|8@1+ (1,0) [0|0] "%" Vector__XXX
 SG_ bat_fan : 0|8@1+ (1,0) [0|0] "%" Vector__XXX

BO_ 2304772608 flowrates: 2 PDU
 SG_ drivetrain_flowrate : 8|8@1+ (1,0) [0|0] "LPM" Vector__XXX
 SG_ battery_flowrate : 0|8@1+ (1,0) [0|0] "LPM" Vector__XXX

BO_ 2304773120 pdu_temps: 2 PDU
 SG_ internal_therm : 0|16@1+ (1,0) [0|0] "C" Vector__XXX

BO_ 2304773632 pdu_can_stats: 4 PDU
 SG_ can_rx_overrun : 24|8@1+ (1,0) [0|0] "" Vector__XXX
 SG_ can_rx_overflow : 16|8@1+ (1,0) [0|0] "" Vector__XXX
 SG_ can_tx_fail : 8|8@1+ (1,0) [0|0] "" Vector__XXX
 SG_ can_tx_overflow : 0|8@1+ (1,0) [0|0] "" Vector__XXX

BO_ 2438991872 pdu_version: 8 PDU
 SG_ git_hash : 0|64@1+ (1,0) [0|0] "" Vector__XXX

BO_ 2170556928 fault_sync_pdu: 3 PDU
 SG_ latched : 16|1@1+ (1,0) [0|0] "" Vector__XXX
 SG_ idx : 0|16@1+ (1,0) [0|0] "" Vector__XXX

BO_ 2304775168 daq_response_PDU_VCAN: 8 PDU
 SG_ daq_response : 0|64@1+ (1,0) [0|0] "" Vector__XXX

BO_ 2306867200 daq_command_MAIN_MODULE_VCAN: 8 DAQ
 SG_ daq_command : 0|64@1+ (1,0) [0|0] "" Vector__XXX

BO_ 2306867712 daq_command_DASHBOARD_VCAN: 8 DAQ
 SG_ daq_command : 0|64@1+ (1,0) [0|0] "" Vector__XXX

BO_ 2306868224 daq_command_A_BOX_VCAN: 8 DAQ
 SG_ daq_command : 0|64@1+ (1,0) [0|0] "" Vector__XXX

BO_ 2306868736 daq_command_PDU_VCAN: 8 DAQ
 SG_ daq_command : 0|64@1+ (1,0) [0|0] "" Vector__XXX

CM_ BO_ 2281701376 "Bitstream download command";
CM_ SG_ 2281701376 d7 "Bitstream data word 7";
CM_ SG_ 2281701376 d6 "Bitstream data word 6";
CM_ SG_ 2281701376 d5 "Bitstream data word 5";
CM_ SG_ 2281701376 d4 "Bitstream data word 4";
CM_ SG_ 2281701376 d3 "Bitstream data word 3";
CM_ SG_ 2281701376 d2 "Bitstream data word 2";
CM_ SG_ 2281701376 d1 "Bitstream data word 1";
CM_ SG_ 2281701376 d0 "Bitstream data word 0";
CM_ BO_ 2281701888 "Bitstream state command";
CM_ SG_ 2281701888 download_size "size for expected bitstream download (bytes)";
CM_ SG_ 2281701888 download_request "Request to download new bitstream";
CM_ BO_ 2281702400 "Bootloader command for main module";
CM_ SG_ 2281702400 data "Bootloader data";
CM_ SG_ 2281702400 cmd "Bootloader Command type";
CM_ BO_ 2281702912 "Bootloader command for dashboard";
CM_ SG_ 2281702912 data "Bootloader data";
CM_ SG_ 2281702912 cmd "Bootloader Command type";
CM_ BO_ 2281703424 "Bootloader command for torque vector";
CM_ SG_ 2281703424 data "Bootloader data";
CM_ SG_ 2281703424 cmd "Bootloader Command type";
CM_ BO_ 2281703936 "Bootloader command for a-box";
CM_ SG_ 2281703936 data "Bootloader data";
CM_ SG_ 2281703936 cmd "Bootloader Command type";
CM_ BO_ 2281704448 "Bootloader command for pdu";
CM_ SG_ 2281704448 data "Bootloader data";
CM_ SG_ 2281704448 cmd "Bootloader Command type";
CM_ BO_ 2281704960 "Bootloader command for l4 testing";
CM_ SG_ 2281704960 data "Bootloader data";
CM_ SG_ 2281704960 cmd "Bootloader Command type";
CM_ BO_ 2281705472 "Bootloader command for f4 testing";
CM_ SG_ 2281705472 data "Bootloader data";
CM_ SG_ 2281705472 cmd "Bootloader Command type";
CM_ BO_ 2281705984 "Bootloader command for f7 testing";
CM_ SG_ 2281705984 data "Bootloader data";
CM_ SG_ 2281705984 cmd "Bootloader Command type";
CM_ BO_ 2281706496 "Bootloader command for DAQ";
CM_ SG_ 2281706496 data "Bootloader data";
CM_ SG_ 2281706496 cmd "Bootloader Command type";
CM_ BO_ 2281707008 "Set a fault";
CM_ SG_ 2281707008 value "Bootloader data";
CM_ SG_ 2281707008 id "Bootloader Command type";
CM_ BO_ 2281707520 "Return control of fault back to the MCU";
CM_ SG_ 2281707520 id "Fault ID";
CM_ BO_ 2283798528 "CAN diagnostics";
CM_ SG_ 2283798528 can_rx_overrun "CAN Rx FIFO overrun count";
CM_ SG_ 2283798528 can_rx_overflow "CAN Rx queue overflow count";
CM_ SG_ 2283798528 can_tx_fail "CAN Tx fail count (due to timeout in mailbox)";
CM_ SG_ 2283798528 can_tx_overflow "CAN Tx queue overflow count";
CM_ BO_ 2283799040 "Queue diagnostics";
CM_ SG_ 2283799040 tcp_tx_overflow "TCP TX queue overflow";
CM_ SG_ 2283799040 sd_rx_overflow "SD RX queue overflow";
CM_ SG_ 2283799040 can1_rx_overflow "CAN RX queue overflow";
CM_ SG_ 2283799040 bcan_rx_overflow "CAN RX buffer overflow";
CM_ BO_ 2418017280 "DAQ version";
CM_ SG_ 2418017280 git_hash "int representation of git short hash";
CM_ BO_ 2285895680 "gps velocity";
CM_ BO_ 2285896192 "gps speed";
CM_ BO_ 2285896704 "gps position";
CM_ BO_ 2285897216 "gps coordinates";
CM_ BO_ 2285897728 "gps time in UTC";
CM_ BO_ 2285898240 "gyroscope from imu";
CM_ BO_ 2285898752 "acceleration from imu";
CM_ BO_ 2285899264 "All torque setpoints and speed setpoints";
CM_ BO_ 2285899776 "Estimated Voc and SOC for HV battery";
CM_ BO_ 2285900288 "Drive Modes";
CM_ BO_ 2285900800 "CAN diagnostics";
CM_ SG_ 2285900800 can_rx_overrun "VCAN Rx FIFO overrun count";
CM_ SG_ 2285900800 can_rx_overflow "VCAN Rx queue overflow count";
CM_ SG_ 2285900800 can_tx_fail "VCAN Tx fail count (due to timeout in mailbox)";
CM_ SG_ 2285900800 can_tx_overflow "VCAN Tx queue overflow count";
CM_ BO_ 2420119040 "Torque Vector version";
CM_ SG_ 2420119040 git_hash "int representation of git short hash";
CM_ BO_ 2151684096 "Fault status message";
CM_ BO_ 2147484290 "Contains the status word and actual values";
CM_ SG_ 2147484290 AMK_ActualTorque "Actual torque value";
CM_ SG_ 2147484290 AMK_ActualSpeed "Actual speed value";
CM_ BO_ 2147484292 "Contains temperatures";
CM_ SG_ 2147484292 AMK_IGBTTemp "IGBT temperature";
CM_ SG_ 2147484292 AMK_InverterTemp "Inverter cold plate temperature";
CM_ SG_ 2147484292 AMK_MotorTemp "Motor temperature";
CM_ BO_ 2147484294 "Contains the status word and actual values";
CM_ SG_ 2147484294 AMK_DCBusVoltage "Voltage of the DC bus";
CM_ SG_ 2147484294 AMK_Status_bDerating "Status word: torque limit activation";
CM_ SG_ 2147484294 AMK_Status_bInverterOn "Status word: Controller enable level";
CM_ SG_ 2147484294 AMK_Status_bQuitInverterOn "Status word: Controller enable ACK";
CM_ SG_ 2147484294 AMK_Status_bDcOn "Status word: HV activation level";
CM_ SG_ 2147484294 AMK_Status_bQuitDcOn "Status word: HV activation ACK";
CM_ SG_ 2147484294 AMK_Status_bWarn "Status word: warning";
CM_ SG_ 2147484294 AMK_Status_bError "Status word: error";
CM_ SG_ 2147484294 AMK_Status_bSystemReady "Status word: system ready";
CM_ SG_ 2147484294 AMK_Status_bReserve "Status word: RESERVED";
CM_ BO_ 2147484296 "All error information";
CM_ SG_ 2147484296 AMK_ErrorInfo1 "Error info";
CM_ SG_ 2147484296 AMK_DiagnosticNumber "Error number";
CM_ BO_ 2147484304 "All error information";
CM_ SG_ 2147484304 AMK_ErrorInfo3 "Error info";
CM_ SG_ 2147484304 AMK_ErrorInfo2 "Error info";
CM_ BO_ 2147484306 "All error information";
CM_ SG_ 2147484306 AMK_PhaseUCurrent "INVA Phase U Current";
CM_ BO_ 2290089984 "charge, State, Current/voltage limits";
CM_ SG_ 2290089984 pack_soc "Pack State of Charge";
CM_ SG_ 2290089984 pack_ccl "Pack charge current limit";
CM_ SG_ 2290089984 pack_dcl "Pack discharge current limit";
CM_ SG_ 2290089984 multi_output_1 "Orion multi purpose output status - unused";
CM_ SG_ 2290089984 multi_enable "Orion multi purpose output with watchdog functionality - unused";
CM_ SG_ 2290089984 multi_output_4 "Orion multi purpose output status - unused";
CM_ SG_ 2290089984 multi_output_3 "Orion multi purpose output status - unused";
CM_ SG_ 2290089984 multi_output_2 "Orion multi purpose output status - unused";
CM_ SG_ 2290089984 multi_input_3 "Orion multi purpose input status - unused";
CM_ SG_ 2290089984 multi_input_2 "Orion multi purpose input status - unused";
CM_ SG_ 2290089984 is_charging "Orion is in \"CHARGE\" mode - controlled by charge power pin";
CM_ SG_ 2290089984 is_ready "Orion is in \"READY\" (discharge) mode";
CM_ SG_ 2290089984 always_on "Orion's low power sleep input is configured";
CM_ SG_ 2290089984 multi_input "Orion multi purpose input status - unused";
CM_ SG_ 2290089984 dtc_status "General error status of OrionBMS";
CM_ SG_ 2290089984 charger_safety "Charger BMS SDC control input - allows current to flow into pack";
CM_ SG_ 2290089984 charge_enable "Permits intermittent charging of pack - AKA Regen (Not currently used)";
CM_ SG_ 2290089984 discharge_enable "Main BMS SDC control input - allows current to be drawn from pack";
CM_ BO_ 2290090496 "Pack current + voltage";
CM_ BO_ 2290091008 "Pack DTC (Diagnostic Trouble Code) Flags";
CM_ SG_ 2290091008 charge_limit_enforce "The orion pack charge curent limit was exceeded - set if violation occured with \"charge enable\" relay";
CM_ SG_ 2290091008 input_psu "Orion is not recieving a stable power supply between 9v and 30v";
CM_ SG_ 2290091008 hv_isolation "BMS has detected a breakdown in HV/LV isolation";
CM_ SG_ 2290091008 redundant_psu "The BMS has lost the \"always on\" power supply, meaning it is no longer redundant (must be configured)";
CM_ SG_ 2290091008 external_comms "Expected CAN messages (must be configured) have not been recieved";
CM_ SG_ 2290091008 thermistor "A thermistor reading has fallen out of it expected operating range";
CM_ SG_ 2290091008 fan_monitor "Voltage on fan monitor (multi-input-3) goes outside provided threshold (if enabled)";
CM_ SG_ 2290091008 weak_pack "Pack state of health estimation falls below provided threshold";
CM_ SG_ 2290091008 cell_asic "Orion has detected a communication problem with its cell voltage measurement circuitry - check fault subcode";
CM_ SG_ 2290091008 max_cellv_o5v "A cell in the pack has been detected to have a cell voltage over 5V";
CM_ SG_ 2290091008 current_sensor "BMS has detected a problem with the current sensor (check fault subcodes)";
CM_ SG_ 2290091008 open_wire "Cell tap wire is either weakly connected or fully disconnected";
CM_ SG_ 2290091008 low_cellv "One or more cells have an extremely low cell voltage (likely dead or wiring problem) (threshold configurable)";
CM_ SG_ 2290091008 weak_cell "Orion has either detected a weak cell within the pack, or a cell that is too far out of balance";
CM_ SG_ 2290091008 cell_balancing_foff "At least one cell balancing circuit is not working";
CM_ SG_ 2290091008 internal_comms "Orion cannot communicate with its isolated cell voltage measurement hardware";
CM_ SG_ 2290091008 pack_overheat "Pack temp has exceeded its max allowable value for >30s";
CM_ SG_ 2290091008 min_cellv_low "An individual cell has gone under its minimum allowable voltage";
CM_ SG_ 2290091008 max_cellv_high "An individual cell has exceeded its maximum allowable voltage";
CM_ SG_ 2290091008 software "Bug in internal software led to invalid operation";
CM_ SG_ 2290091008 heatsink_thermistor "Orion can't detect it's internal temperature";
CM_ SG_ 2290091008 internal_hardware "Orion has detected a hardware failure within itself";
CM_ SG_ 2290091008 charger_safety_relay "Charge Current limit exceeded - set if violation occured with \"charger safety\" relay";
CM_ SG_ 2290091008 discharge_limit_enforce "Discharge current limit exceed";
CM_ BO_ 2292187136 "Throttle and brake values";
CM_ SG_ 2292187136 brake_pot "Reading for potentiometer on brake pedal [OLD, no longer used]";
CM_ SG_ 2292187136 brake_right "Raw sensor reading from right (rear) brake sensor";
CM_ SG_ 2292187136 brake "Raw sensor reading from left (front) brake sensor";
CM_ SG_ 2292187136 throttle_right "Raw sensor reading from right throttle sensor";
CM_ SG_ 2292187136 throttle "Raw sensor reading from left throttle sensor";
CM_ BO_ 2292187648 "Shockpot readings from front left and front right";
CM_ SG_ 2292187648 right_shock "Travel distance of front right shockpot";
CM_ SG_ 2292187648 left_shock "Travel distance of front left shockpot";
CM_ BO_ 2292188160 "Load Sensor normal force readings from front left and right";
CM_ BO_ 2292188672 "Cooling Pump/Fan requests from Dash LCD";
CM_ BO_ 2292189184 "Filtered throttle and brake values";
CM_ SG_ 2292189184 brake "Processed brake request from driver";
CM_ SG_ 2292189184 throttle "Official throttle request from driver";
CM_ BO_ 2292189696 "Car start button pressed";
CM_ BO_ 2292190208 "periodic dashboard MCU temp";
CM_ BO_ 2292190720 "Voltage rail measurements on dashboard";
CM_ BO_ 2292191232 "periodic dashboard vcu parameters";
CM_ BO_ 2292191744 "Log enable request for DAQ SD card";
CM_ SG_ 2292191744 logging_enabled "Request SD card logging to begin";
CM_ BO_ 2292192256 "CAN diagnostics";
CM_ SG_ 2292192256 can_rx_overrun "CAN Rx FIFO overrun count";
CM_ SG_ 2292192256 can_rx_overflow "CAN Rx queue overflow count";
CM_ SG_ 2292192256 can_tx_fail "CAN Tx fail count (due to timeout in mailbox)";
CM_ SG_ 2292192256 can_tx_overflow "CAN Tx queue overflow count";
CM_ BO_ 2426410496 "Dashboard version";
CM_ SG_ 2426410496 git_hash "int representation of git short hash";
CM_ BO_ 2157975552 "Fault status message";
CM_ BO_ 2292193792 "daq response from node DASHBOARD";
CM_ BO_ 2294284288 "Heart beat message for main module";
CM_ SG_ 2294284288 precharge_state "Status of Precharge (complete vs not)";
CM_ SG_ 2294284288 car_state "Main car state";
CM_ BO_ 2294284800 "Water temp of cooling loops";
CM_ SG_ 2294284800 drivetrain_out_temp "Out flow temperature of drivetrain coolant loop";
CM_ SG_ 2294284800 drivetrain_in_temp "In flow temperature of drivetrain coolant loop";
CM_ SG_ 2294284800 battery_out_temp "Out flow temperature of battery coolant loop";
CM_ SG_ 2294284800 battery_in_temp "In flow temperature of battery coolant loop";
CM_ BO_ 2294285312 "Gearbox temps";
CM_ SG_ 2294285312 r_temp "Temperature of right gearbox";
CM_ SG_ 2294285312 l_temp "Temperature of left gearbox";
CM_ BO_ 2147485632 "Steering sensor configuration";
CM_ BO_ 2294286336 "Load Sensor readings from left and right";
CM_ SG_ 2294286336 right_load_sensor "Right Normal Force";
CM_ SG_ 2294286336 left_load_sensor "Left Normal Force";
CM_ BO_ 2294286848 "Shockpot readings from left and right";
CM_ SG_ 2294286848 right_shock "Right Shockpot Travel";
CM_ SG_ 2294286848 left_shock "Left Shockpot Travel";
CM_ BO_ 2294287360 "performance metrics of MCU";
CM_ SG_ 2294287360 sched_error "PSCHED Error Flags (bit #)
 0 - N/A
1 - no free task
2 - FG Miss
3 - BG Miss
4 - Individual FG Miss";
CM_ SG_ 2294287360 background_use "Percent of the 1ms loop time used by background tasks";
CM_ SG_ 2294287360 foreground_use "Percent of the 1ms loop time used by foreground tasks";
CM_ SG_ 2294287360 sched_skips "Number of loop misses (execution time was skipped)";
CM_ BO_ 2294287872 "CAN diagnostics";
CM_ SG_ 2294287872 can2_rx_overrun "MCAN Rx FIFO overrun count";
CM_ SG_ 2294287872 can1_rx_overrun "VCAN Rx FIFO overrun count";
CM_ SG_ 2294287872 can_rx_queue_overflow "CAN Rx queue overflow count";
CM_ SG_ 2294287872 can2_tx_fail "CAN Tx fail count for MCAN (due to timeout in mailbox)";
CM_ SG_ 2294287872 can1_tx_fail "CAN Tx fail count for VCAN (due to timeout in mailbox)";
CM_ SG_ 2294287872 can2_tx_queue_overflow "MCAN Tx queue overflow count";
CM_ SG_ 2294287872 can1_tx_queue_overflow "VCAN Tx queue overflow count";
CM_ BO_ 2294288384 "Messages ignored by MC";
CM_ SG_ 2294288384 noise_l "Num of skipped MC UART msgs";
CM_ SG_ 2294288384 noise_r "Num of skipped MC UART msgs";
CM_ BO_ 2294288896 "Contains control word and setpoints";
CM_ SG_ 2294288896 AMK_NegativeTorqueLimit "Negative Torque Limit";
CM_ SG_ 2294288896 AMK_PositiveTorqueLimit "Positive Torque Limit";
CM_ SG_ 2294288896 AMK_TorqueSetpoint "Torque setpoint";
CM_ SG_ 2294288896 AMK_Control_bReserve2 "Control word: RESERVED";
CM_ SG_ 2294288896 AMK_Control_bErrorReset "Control word: remove error";
CM_ SG_ 2294288896 AMK_Control_bEnable "Control word: driver enable";
CM_ SG_ 2294288896 AMK_Control_bDcOn "Control word: HV activation";
CM_ SG_ 2294288896 AMK_Control_bInverterOn "Control word: controller enable";
CM_ SG_ 2294288896 AMK_Control_bReserve "Control word: RESERVED";
CM_ BO_ 2294289408 "Contains control word and setpoints";
CM_ SG_ 2294289408 AMK_NegativeTorqueLimit "Negative Torque Limit";
CM_ SG_ 2294289408 AMK_PositiveTorqueLimit "Positive Torque Limit";
CM_ SG_ 2294289408 AMK_TorqueSetpoint "Torque setpoint";
CM_ SG_ 2294289408 AMK_Control_bReserve2 "Control word: RESERVED";
CM_ SG_ 2294289408 AMK_Control_bErrorReset "Control word: remove error";
CM_ SG_ 2294289408 AMK_Control_bEnable "Control word: driver enable";
CM_ SG_ 2294289408 AMK_Control_bDcOn "Control word: HV activation";
CM_ SG_ 2294289408 AMK_Control_bInverterOn "Control word: controller enable";
CM_ SG_ 2294289408 AMK_Control_bReserve "Control word: RESERVED";
CM_ BO_ 2294289920 "rear drivline heart beat";
CM_ SG_ 2294289920 rear_right_last_link_error "Error reason for failed MC communication link attempt";
CM_ SG_ 2294289920 rear_right_motor_link "State of Connection attempt to MC";
CM_ SG_ 2294289920 rear_right_motor "Connection State of Rear Right Motor";
CM_ SG_ 2294289920 rear_left_last_link_error "Error reason for failed MC communication link attempt";
CM_ SG_ 2294289920 rear_left_motor_link "State of Connection attempt to MC";
CM_ SG_ 2294289920 rear_left_motor "Connection State of Rear Left Motor";
CM_ BO_ 2294290432 "DC Current and Voltage of the motors";
CM_ BO_ 2294290944 "Shutdown Circuit Status";
CM_ BO_ 2294291456 "Temperature of motor controllers and motors";
CM_ BO_ 2294291968 "Rear Wheel speeds from motor controllers";
CM_ BO_ 2294292480 "Rear Wheel speeds from motor controllers";
CM_ BO_ 2428510720 "Main version";
CM_ SG_ 2428510720 git_hash "int representation of git short hash";
CM_ BO_ 2160075776 "Fault status message";
CM_ BO_ 2294294016 "daq response from node MAIN_MODULE";
CM_ BO_ 2296381440 "Main Module Bootloader response";
CM_ BO_ 2296381952 "Dashboard Bootloader response";
CM_ BO_ 2296382464 "Torque Vector Bootloader response";
CM_ BO_ 2296382976 "Accumulator Box PCB Bootloader response";
CM_ BO_ 2296383488 "PDU Bootloader response";
CM_ BO_ 2296384000 "L4 Test Bootloader response";
CM_ BO_ 2296384512 "F4 Test Bootloader response";
CM_ BO_ 2296385024 "F7 Test Bootloader response";
CM_ BO_ 2296385536 "DAQ Bootloader response";
CM_ BO_ 2147484291 "Contains the status word and actual values";
CM_ SG_ 2147484291 AMK_ActualTorque "Actual torque value";
CM_ SG_ 2147484291 AMK_ActualSpeed "Actual speed value";
CM_ BO_ 2147484293 "Contains temperatures";
CM_ SG_ 2147484293 AMK_IGBTTemp "IGBT temperature";
CM_ SG_ 2147484293 AMK_InverterTemp "Inverter cold plate temperature";
CM_ SG_ 2147484293 AMK_MotorTemp "Motor temperature";
CM_ BO_ 2147484295 "Contains the status word and actual values";
CM_ SG_ 2147484295 AMK_DCBusVoltage "Voltage of the DC bus";
CM_ SG_ 2147484295 AMK_Status_bDerating "Status word: torque limit activation";
CM_ SG_ 2147484295 AMK_Status_bInverterOn "Status word: Controller enable level";
CM_ SG_ 2147484295 AMK_Status_bQuitInverterOn "Status word: Controller enable ACK";
CM_ SG_ 2147484295 AMK_Status_bDcOn "Status word: HV activation level";
CM_ SG_ 2147484295 AMK_Status_bQuitDcOn "Status word: HV activation ACK";
CM_ SG_ 2147484295 AMK_Status_bWarn "Status word: warning";
CM_ SG_ 2147484295 AMK_Status_bError "Status word: error";
CM_ SG_ 2147484295 AMK_Status_bSystemReady "Status word: system ready";
CM_ SG_ 2147484295 AMK_Status_bReserve "Status word: RESERVED";
CM_ BO_ 2147484297 "All error information";
CM_ SG_ 2147484297 AMK_ErrorInfo1 "Error info";
CM_ SG_ 2147484297 AMK_DiagnosticNumber "Error number";
CM_ BO_ 2147484305 "All error information";
CM_ SG_ 2147484305 AMK_ErrorInfo3 "Error info";
CM_ SG_ 2147484305 AMK_ErrorInfo2 "Error info";
CM_ BO_ 2147484307 "All error information";
CM_ SG_ 2147484307 AMK_PhaseUCurrent "INVB Phase U Current";
CM_ BO_ 2147484336 "Standard steering angle and speed";
CM_ SG_ 2147484336 Trim "Sensor information validity flag (invalid if 0)";
CM_ SG_ 2147484336 Cal "Sensor calibration status";
CM_ SG_ 2147484336 Ok "Sensor failure status";
CM_ SG_ 2147484336 LWS_SPEED "Angular speed of steering input";
CM_ SG_ 2147484336 LWS_ANGLE "Steering Angle";
CM_ BO_ 2302672896 "heart beat for precharge";
CM_ SG_ 2302672896 BMS "Fault State of BMS";
CM_ SG_ 2302672896 IMD "Fault State of IMD";
CM_ BO_ 2550588916 "Charge voltage and current request to ELCON charger";
CM_ SG_ 2550588916 charge_disable "Disable charging";
CM_ SG_ 2550588916 current_limit "Requested charge current";
CM_ SG_ 2550588916 voltage_limit "Requested charge voltage";
CM_ BO_ 2302673920 "Number of wonky thermistors on pack";
CM_ SG_ 2302673920 E_right "Number of thermistors > 1.5v";
CM_ SG_ 2302673920 E_left "Number of thermistors > 1.5v";
CM_ SG_ 2302673920 D_right "Number of thermistors > 1.5v";
CM_ SG_ 2302673920 D_left "Number of thermistors > 1.5v";
CM_ SG_ 2302673920 C_right "Number of thermistors > 1.5v";
CM_ SG_ 2302673920 C_left "Number of thermistors > 1.5v";
CM_ SG_ 2302673920 B_right "Number of thermistors > 1.5v";
CM_ SG_ 2302673920 B_left "Number of thermistors > 1.5v";
CM_ SG_ 2302673920 A_right "Number of thermistors > 1.5v";
CM_ SG_ 2302673920 A_left "Number of thermistors > 1.5v";
CM_ BO_ 2302674432 "Statistics about current charge cycle";
CM_ SG_ 2302674432 current "Instantaneous charge current";
CM_ SG_ 2302674432 voltage "Instantaneous charge voltage";
CM_ SG_ 2302674432 charge_enable "Charge mode enabled";
CM_ SG_ 2302674432 power "Instantaneous charge power";
CM_ BO_ 2302674944 "maximum cell temperature for the whole pack";
CM_ BO_ 2302675456 "Average cell temperature for each module";
CM_ BO_ 2302675968 "Average cell temperature for each module";
CM_ BO_ 2302676480 "Max cell temperature for a, b, and c";
CM_ BO_ 2302676992 "Max cell temperature for d and e";
CM_ BO_ 2302677504 "Min cell temperature for each a, b, and c";
CM_ BO_ 2302678016 "Min cell temperature for each d and e";
CM_ BO_ 2302678528 "Raw cell temperature for each module of thermistor at index";
CM_ BO_ 2302679040 "Raw cell temperature for each module of thermistor at index";
CM_ BO_ 2302679552 "Raw cell temperature for each module of thermistor at index";
CM_ BO_ 2302680064 "Raw cell temperature for each module of thermistor at index";
CM_ BO_ 2302680576 "Raw cell temperature for each module of thermistor at index";
CM_ BO_ 2302681088 "CAN diagnostics";
CM_ SG_ 2302681088 can2_rx_overrun "CCAN (Charger CAN) Rx FIFO overrun count";
CM_ SG_ 2302681088 can1_rx_overrun "VCAN Rx FIFO overrun count";
CM_ SG_ 2302681088 can_rx_queue_overflow "CAN Rx queue overflow count";
CM_ SG_ 2302681088 can2_tx_fail "CAN Tx fail count for CCAN (Charger CAN) (due to timeout in mailbox)";
CM_ SG_ 2302681088 can1_tx_fail "CAN Tx fail count for VCAN (due to timeout in mailbox)";
CM_ SG_ 2302681088 can2_tx_queue_overflow "CCAN (Charger CAN) Tx queue overflow count";
CM_ SG_ 2302681088 can1_tx_queue_overflow "VCAN Tx queue overflow count";
CM_ BO_ 2302681600 "Current sense value for channel 1 and channel 2 of pack current sensor";
CM_ SG_ 2302681600 current_channel_2 "Channel 2 used to measure higher pack currents, lower fidelity than channel 1";
CM_ SG_ 2302681600 current_channel_1 "Channel 1 used for BSPD circuit, Higher fidelity, but maxes out at a low amperage";
CM_ BO_ 2436899840 "ABox version";
CM_ SG_ 2436899840 git_hash "int representation of git short hash";
CM_ BO_ 2168464896 "Fault status message";
CM_ BO_ 2302683136 "daq response from node A_BOX";
CM_ BO_ 2304770048 "PDU voltage rail readings";
CM_ SG_ 2304770048 out_3v3 "3v3 rail output voltage";
CM_ SG_ 2304770048 out_5v "5v rail output voltage";
CM_ SG_ 2304770048 in_24v "Unregulated 24V input";
CM_ BO_ 2304770560 "PDU rail currents";
CM_ SG_ 2304770560 i_5v "5v rail current";
CM_ SG_ 2304770560 i_24v "Unregulated 24V rail current";
CM_ BO_ 2304771072 "PDU pump and fan currents";
CM_ BO_ 2304771584 "Other PDU currents";
CM_ BO_ 2304772096 "outputs to coolant loops";
CM_ SG_ 2304772096 dt_pump "Drivetrain pump enabled";
CM_ SG_ 2304772096 bat_pump_aux "Auxilliary output enable request";
CM_ SG_ 2304772096 bat_pump "Battery pump enabled";
CM_ SG_ 2304772096 dt_fan "Drivetrain fan speed request";
CM_ SG_ 2304772096 bat_fan "Battery fan speed request";
CM_ BO_ 2304772608 "Flowrate cooling loops";
CM_ SG_ 2304772608 drivetrain_flowrate "Flow rate for drivetrain coolant loop";
CM_ SG_ 2304772608 battery_flowrate "Flow rate for battery coolant loop";
CM_ BO_ 2304773120 "PDU board temperatures";
CM_ SG_ 2304773120 internal_therm "Temperature from internal thermistor";
CM_ BO_ 2304773632 "CAN diagnostics";
CM_ SG_ 2304773632 can_rx_overrun "CAN Rx FIFO overrun count";
CM_ SG_ 2304773632 can_rx_overflow "CAN Rx queue overflow count";
CM_ SG_ 2304773632 can_tx_fail "CAN Tx fail count (due to timeout in mailbox)";
CM_ SG_ 2304773632 can_tx_overflow "CAN Tx queue overflow count";
CM_ BO_ 2438991872 "PDU version";
CM_ SG_ 2438991872 git_hash "int representation of git short hash";
CM_ BO_ 2170556928 "Fault status message";
CM_ BO_ 2304775168 "daq response from node PDU";
CM_ BO_ 2306867200 "daq command for node MAIN_MODULE_VCAN";
CM_ BO_ 2306867712 "daq command for node DASHBOARD_VCAN";
CM_ BO_ 2306868224 "daq command for node A_BOX_VCAN";
CM_ BO_ 2306868736 "daq command for node PDU_VCAN";
